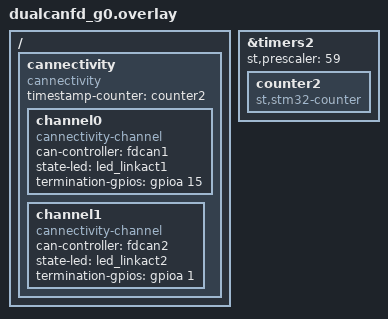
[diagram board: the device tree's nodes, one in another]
#include <zephyr/dt-bindings/gpio/gpio.h>
#include "../app.overlay"

/ {
	cannectivity: cannectivity {
		compatible = "cannectivity";
		timestamp-counter = <&counter2>;

		channel0 {
			compatible = "cannectivity-channel";
			can-controller = <&fdcan1>;
			state-led = <&led_linkact1>;
			termination-gpios = <&gpioa 15 GPIO_ACTIVE_HIGH>;
		};

		channel1 {
			compatible = "cannectivity-channel";
			can-controller = <&fdcan2>;
			state-led = <&led_linkact2>;
			termination-gpios = <&gpioa 1 GPIO_ACTIVE_HIGH>;
		};
	};
};

&timers2 {
	status = "okay";
	st,prescaler = <59>;

	counter2: counter2 {
		compatible = "st,stm32-counter";
		status = "okay";
	};
};
